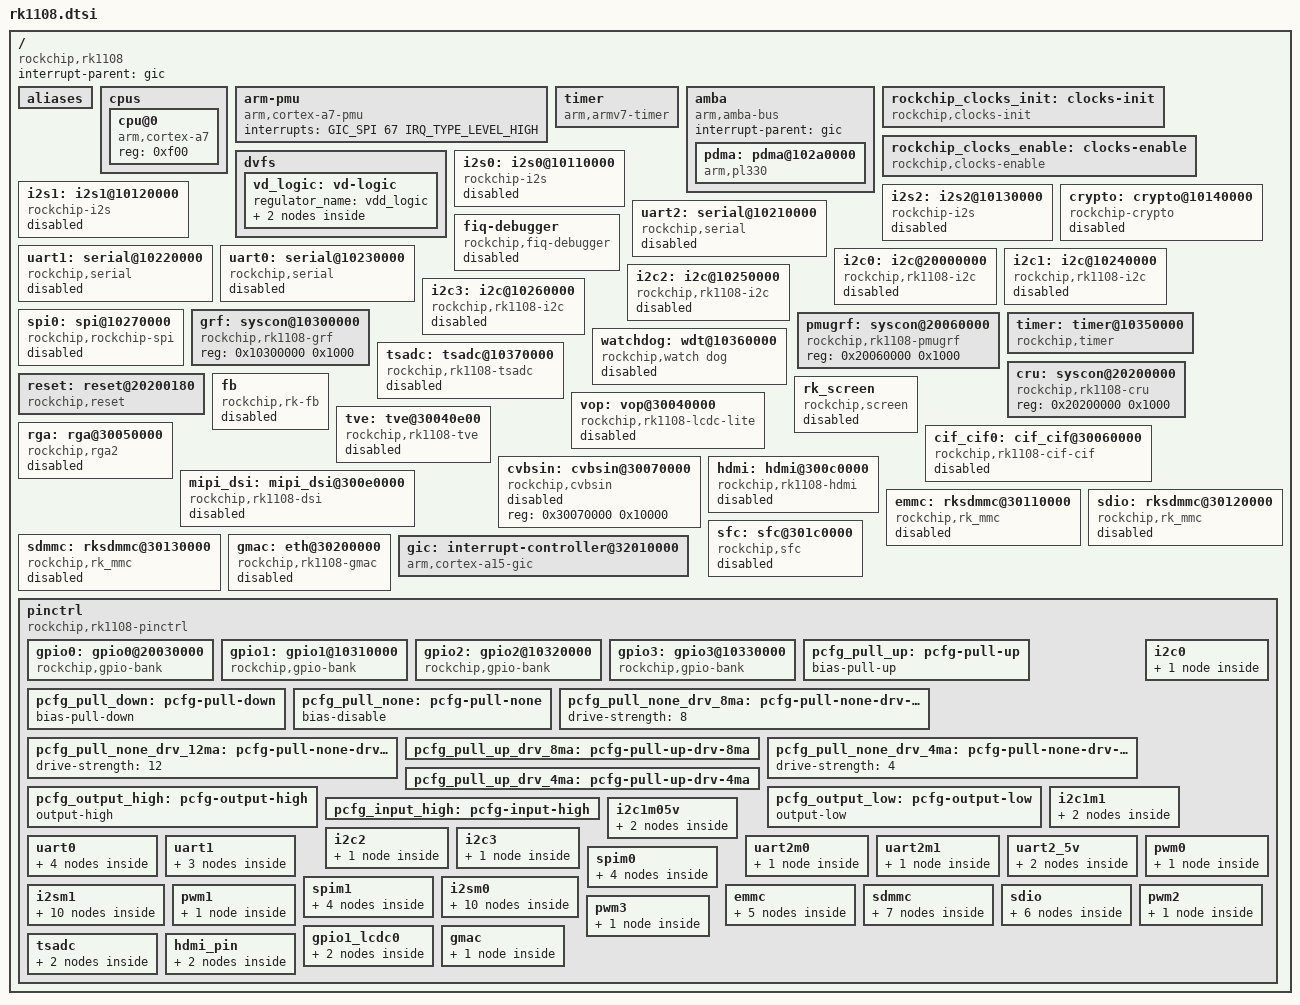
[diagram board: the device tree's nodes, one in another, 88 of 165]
/*
 * Copyright (c) 2016 Fuzhou Rockchip Electronics Co., Ltd
 *
 * This file is dual-licensed: you can use it either under the terms
 * of the GPL or the X11 license, at your option. Note that this dual
 * licensing only applies to this file, and not this project as a
 * whole.
 *
 *  a) This library is free software; you can redistribute it and/or
 *     modify it under the terms of the GNU General Public License as
 *     published by the Free Software Foundation; either version 2 of the
 *     License, or (at your option) any later version.
 *
 *     This library is distributed in the hope that it will be useful,
 *     but WITHOUT ANY WARRANTY; without even the implied warranty of
 *     MERCHANTABILITY or FITNESS FOR A PARTICULAR PURPOSE.  See the
 *     GNU General Public License for more details.
 *
 * Or, alternatively,
 *
 *  b) Permission is hereby granted, free of charge, to any person
 *     obtaining a copy of this software and associated documentation
 *     files (the "Software"), to deal in the Software without
 *     restriction, including without limitation the rights to use,
 *     copy, modify, merge, publish, distribute, sublicense, and/or
 *     sell copies of the Software, and to permit persons to whom the
 *     Software is furnished to do so, subject to the following
 *     conditions:
 *
 *     The above copyright notice and this permission notice shall be
 *     included in all copies or substantial portions of the Software.
 *
 *     THE SOFTWARE IS PROVIDED "AS IS", WITHOUT WARRANTY OF ANY KIND,
 *     EXPRESS OR IMPLIED, INCLUDING BUT NOT LIMITED TO THE WARRANTIES
 *     OF MERCHANTABILITY, FITNESS FOR A PARTICULAR PURPOSE AND
 *     NONINFRINGEMENT. IN NO EVENT SHALL THE AUTHORS OR COPYRIGHT
 *     HOLDERS BE LIABLE FOR ANY CLAIM, DAMAGES OR OTHER LIABILITY,
 *     WHETHER IN AN ACTION OF CONTRACT, TORT OR OTHERWISE, ARISING
 *     FROM, OUT OF OR IN CONNECTION WITH THE SOFTWARE OR THE USE OR
 *     OTHER DEALINGS IN THE SOFTWARE.
 */

#include <dt-bindings/pinctrl/rockchip.h>
#include <dt-bindings/gpio/gpio.h>
#include <dt-bindings/clock/rk_system_status.h>
#include <dt-bindings/interrupt-controller/arm-gic.h>
#include <dt-bindings/rkmipi/mipi_dsi.h>
#include "rk1108-clocks.dtsi"
#include "skeleton.dtsi"
#include <dt-bindings/rkfb/rk_fb.h>

/ {
	compatible = "rockchip,rk1108";
	interrupt-parent = <&gic>;

	aliases {
		i2c0 = &i2c0;
		i2c1 = &i2c1;
		i2c2 = &i2c2;
		i2c3 = &i2c3;
		serial0 = &uart0;
		serial1 = &uart1;
		serial2 = &uart2;
		spi0 = &spi0;
	};

	cpus {
		#address-cells = <1>;
		#size-cells = <0>;

		cpu@0 {
			device_type = "cpu";
			compatible = "arm,cortex-a7";
			reg = <0xf00>;
		};
	};

	arm-pmu {
		compatible = "arm,cortex-a7-pmu";
		interrupts = <GIC_SPI 67 IRQ_TYPE_LEVEL_HIGH>;
	};

	timer {
		compatible = "arm,armv7-timer";
		interrupts = <GIC_PPI 13
			      (GIC_CPU_MASK_SIMPLE(4) | IRQ_TYPE_LEVEL_HIGH)>,
			     <GIC_PPI 14
			      (GIC_CPU_MASK_SIMPLE(4) | IRQ_TYPE_LEVEL_HIGH)>;
		clock-frequency = <24000000>;
	};

	amba {
		#address-cells = <1>;
		#size-cells = <1>;
		compatible = "arm,amba-bus";
		interrupt-parent = <&gic>;
		ranges;

		pdma: pdma@102a0000 {
			compatible = "arm,pl330", "arm,primecell";
			reg = <0x102a0000 0x4000>;
			clocks = <&clk_gates12 2>;
			clock-names = "apb_pclk";
			interrupts = <GIC_SPI 0 IRQ_TYPE_LEVEL_HIGH>;
			#dma-cells = <1>;
		};
	};

	rockchip_clocks_init: clocks-init{
		compatible = "rockchip,clocks-init";
		rockchip,clocks-init-parent =
			<&aclk_bus_pre &clk_gpll>, <&aclk_peri &clk_gpll>;
		rockchip,clocks-init-rate =
			<&clk_gpll 1248000000>, <&clk_core 816000000>,
			<&clk_dsp 416000000>, <&aclk_bus_pre 156000000>,
			<&hclk_bus_pre 156000000>, <&pclk_bus_pre 78000000>,
			<&aclk_peri 156000000>, <&hclk_peri 156000000>,
			<&pclk_peri 78000000>, <&aclk_vio0_pre 312000000>,
			<&aclk_vio1_pre 312000000>, <&hclk_vio_pre 156000000>,
			<&pclk_vio_pre 156000000>, <&aclk_rkvdec_pre 312000000>,
			<&aclk_vpu_pre 312000000>, <&clk_hevc_cabac 312000000>,
			<&clk_hevc_core 312000000>, <&aclk_rkvenc_pre 312000000>,
			<&clk_venc_core 312000000>;
	};

	rockchip_clocks_enable: clocks-enable {
		compatible = "rockchip,clocks-enable";
		clocks =
			/* PLL */
			<&clk_apll>,
			<&clk_dpll>,
			<&clk_gpll>,

			/* PD_CORE */
			<&clk_core>,
			<&pclk_dbg>,
			<&aclk_core>,
			<&clk_gates11 0>, /* aclk_core_niu */
			<&clk_gates11 1>, /* pclk_core_niu */
			<&clk_gates10 9>, /* clk_ddrphy4x */

			/* PD_BUS */
			<&clk_gates12 1>, /* clk_intmem0 */
			<&clk_gates12 2>, /* aclk_dmac_bus */
			<&clk_gates12 3>, /* hclk_rom */
			<&clk_gates12 4>, /* pclk_ddr_upctl */
			<&clk_gates12 5>, /* clk_ddr_upctl */
			<&clk_gates12 6>, /* pclk_ddrmon */
			<&clk_gates12 12>, /* pclk_efuse0 */
			<&clk_gates12 13>, /* pclk_efuse1 */
			<&clk_gates14 0>, /* pclk_grf */
			<&clk_gates14 1>, /* aclk_niu */
			<&clk_gates14 2>, /* pclk_mschniu */
			<&clk_gates14 3>, /* pclk_top_niu */
			<&clk_gates14 4>, /* pclk_ddrphy */
			<&clk_gates14 5>, /* pclk_cru */
			<&clk_gates14 14>, /* pclk_usbgrf */

			/* PD_PERI */
			<&clk_gates15 11>, /* aclk_peri_niu */
			<&clk_gates15 12>, /* hclk_peri_niu */
			<&clk_gates15 13>, /* pclk_peri_niu */

			/* PD_PMU */
			<&clk_gates10 0>, /* pclk_pmu */
			<&clk_gates10 1>, /* pclk_intmem1 */
			<&clk_gates10 3>, /* pclk_pmugrf */
			<&clk_gates10 4>, /* pclk_pmu_niu */

			/* PD_DSP */
			<&clk_gates11 8>, /* aclk_dsp_edp_perf */
			<&clk_gates16 4>, /* pclk_dsp_iop_niu */
			<&clk_gates16 5>, /* aclk_dsp_epp_niu */
			<&clk_gates16 6>, /* aclk_dsp_edp_niu */
			<&clk_gates16 7>, /* pclk_dsp_dbg_niu */
			<&clk_gates16 8>, /* pclk_dsp_cfg_niu */
			<&clk_gates16 9>, /* pclk_ceva_pfm_mon */
			<&clk_gates16 14>, /* aclk_dsp_edap_niu */
			<&clk_gates16 15>, /* aclk_dsp_epp_perf */

			/* PD_VIDEO */
			<&clk_gates19 4>, /* aclk_rkvdec_niu */
			<&clk_gates19 5>, /* hclk_rkvdec_niu */
			<&clk_gates19 6>, /* aclk_vpu_niu */
			<&clk_gates19 10>, /* hclk_rkvenc_niu */
			<&clk_gates19 11>, /* aclk_rkvenc_niu */

			<&clk_gates1 9>, /* clk_timer0 */
			<&clk_gates1 10>, /* clk_timer1 */

			<&clk_gates0 3>; /* clk_jtag */
	};

	dvfs {
		vd_logic: vd-logic {
			regulator_name = "vdd_logic";
			pd_core {
				clk_core_dvfs_table: clk_core {
					operating-points = <
						/* KHz    uV */
						312000 1000000
						504000 1000000
						816000 1000000
						>;
					status = "disabled";
				};
			};
		};
	};

	i2s0: i2s0@10110000 {
		compatible = "rockchip-i2s";
		reg = <0x10110000 0x1000>;
		i2s-id = <0>;
		clocks = <&clk_i2s0>, <&i2s0_clkout>, <&clk_gates12 7>;
		clock-names = "i2s_clk", "i2s_mclk", "i2s_hclk";
		interrupts = <GIC_SPI 23 IRQ_TYPE_LEVEL_HIGH>;
		dmas = <&pdma 11>, <&pdma 12>;
		#dma-cells = <2>;
		dma-names = "tx", "rx";
		status = "disabled";
	};

	i2s1: i2s1@10120000 {
		compatible = "rockchip-i2s";
		reg = <0x10120000 0x1000>;
		i2s-id = <1>;
		clocks = <&clk_i2s1>, <&clk_gates12 8>;
		clock-names = "i2s_clk", "i2s_hclk";
		interrupts = <GIC_SPI 24 IRQ_TYPE_LEVEL_HIGH>;
		dmas = <&pdma 0>, <&pdma 1>;
		#dma-cells = <2>;
		dma-names = "tx", "rx";
		status = "disabled";
	};

	i2s2: i2s2@10130000 {
		compatible = "rockchip-i2s";
		reg = <0x10130000 0x1000>;
		i2s-id = <2>;
		clocks = <&clk_i2s2>, <&clk_gates12 9>;
		clock-names = "i2s_clk", "i2s_hclk";
		interrupts = <GIC_SPI 25 IRQ_TYPE_LEVEL_HIGH>;
		dmas = <&pdma 15>, <&pdma 16>;
		#dma-cells = <2>;
		dma-names = "tx", "rx";
		status = "disabled";
	};

	crypto: crypto@10140000 {
		compatible = "rockchip-crypto";
		reg = <0x10140000 0x10000>;
		interrupts = <GIC_SPI 26 IRQ_TYPE_LEVEL_HIGH>;
		interrupt-names = "irq_crypto";
		clocks = <&clk_crypto>, <&clk_gates12 11>, <&clk_gates12 10>;
		clock-names = "clk_crypto", "hclk_crypto", "aclk_crypto";
		status = "disabled";
	};

	uart2: serial@10210000 {
		compatible = "rockchip,serial";
		reg = <0x10210000 0x100>;
		interrupts = <GIC_SPI 46 IRQ_TYPE_LEVEL_HIGH>;
		clock-frequency = <24000000>;
		clocks = <&clk_uart2>, <&clk_gates13 12>;
		clock-names = "sclk_uart", "pclk_uart";
		reg-shift = <2>;
		reg-io-width = <4>;
		dmas = <&pdma 6>, <&pdma 7>;
		#dma-cells = <2>;
		pinctrl-names = "default";
		pinctrl-0 = <&uart2m1_xfer>;
		status = "disabled";
	};

	uart1: serial@10220000 {
		compatible = "rockchip,serial";
		reg = <0x10220000 0x100>;
		interrupts = <GIC_SPI 45 IRQ_TYPE_LEVEL_HIGH>;
		clock-frequency = <24000000>;
		clocks = <&clk_uart1>, <&clk_gates13 11>;
		clock-names = "sclk_uart", "pclk_uart";
		reg-shift = <2>;
		reg-io-width = <4>;
		dmas = <&pdma 4>, <&pdma 5>;
		#dma-cells = <2>;
		pinctrl-names = "default";
		pinctrl-0 = <&uart1_xfer &uart1_cts &uart1_rts>;
		status = "disabled";
	};

	uart0: serial@10230000 {
		compatible = "rockchip,serial";
		reg = <0x10230000 0x100>;
		interrupts = <GIC_SPI 44 IRQ_TYPE_LEVEL_HIGH>;
		clock-frequency = <24000000>;
		clocks = <&clk_uart0>, <&clk_gates13 10>;
		clock-names = "sclk_uart", "pclk_uart";
		reg-shift = <2>;
		reg-io-width = <4>;
		dmas = <&pdma 2>, <&pdma 3>;
		#dma-cells = <2>;
		pinctrl-names = "default";
		pinctrl-0 = <&uart0_xfer &uart0_cts &uart0_rts>;
		status = "disabled";
	};

	fiq-debugger {
		compatible = "rockchip,fiq-debugger";
		rockchip,serial-id = <0>;
		rockchip,signal-irq = <159>;
		rockchip,wake-irq = <0>;
		rockchip,irq-mode-enable = <0>;  /* If enable uart uses irq instead of fiq */
		rockchip,baudrate = <1500000>;  /* Only 115200 and 1500000 */
		pinctrl-names = "default";
		pinctrl-0 = <&uart0_xfer>;
		status = "disabled";
	};

	i2c0: i2c@20000000 {
		compatible = "rockchip,rk1108-i2c";
		reg = <0x20000000 0x1000>;
		interrupts = <GIC_SPI 30 IRQ_TYPE_LEVEL_HIGH>;
		#address-cells = <1>;
		#size-cells = <0>;
		clocks = <&clk_i2c0>, <&clk_gates10 5>;
		clock-names = "i2c", "pclk";
		pinctrl-names = "default";
		pinctrl-0 = <&i2c0_xfer>;
		status = "disabled";
	};

	i2c1: i2c@10240000 {
		compatible = "rockchip,rk1108-i2c";
		reg = <0x10240000 0x1000>;
		interrupts = <GIC_SPI 31 IRQ_TYPE_LEVEL_HIGH>;
		#address-cells = <1>;
		#size-cells = <0>;
		clocks = <&clk_i2c1>, <&clk_gates13 0>;
		clock-names = "i2c", "pclk";
		pinctrl-names = "default";
		pinctrl-0 = <&i2c1m1_xfer>;
		status = "disabled";
	};

	i2c2: i2c@10250000 {
		compatible = "rockchip,rk1108-i2c";
		reg = <0x10250000 0x1000>;
		interrupts = <GIC_SPI 32 IRQ_TYPE_LEVEL_HIGH>;
		#address-cells = <1>;
		#size-cells = <0>;
		clocks = <&clk_i2c2>, <&clk_gates13 1>;
		clock-names = "i2c", "pclk";
		pinctrl-names = "default";
		pinctrl-0 = <&i2c2_xfer>;
		status = "disabled";
	};

	i2c3: i2c@10260000 {
		compatible = "rockchip,rk1108-i2c";
		reg = <0x10260000 0x1000>;
		interrupts = <GIC_SPI 33 IRQ_TYPE_LEVEL_HIGH>;
		#address-cells = <1>;
		#size-cells = <0>;
		clocks = <&clk_i2c3>, <&clk_gates13 2>;
		clock-names = "i2c", "pclk";
		pinctrl-names = "default";
		pinctrl-0 = <&i2c3_xfer>;
		status = "disabled";
	};

	spi0: spi@10270000 {
		compatible = "rockchip,rockchip-spi";
		reg = <0x10270000 0x1000>;
		interrupts = <GIC_SPI 37 IRQ_TYPE_LEVEL_HIGH>;
		#address-cells = <1>;
		#size-cells = <0>;
		rockchip,spi-src-clk = <0>;
		num-cs = <2>;
		clocks =<&clk_spi>, <&clk_gates13 5>;
		clock-names = "spi", "pclk_spi0";
		status = "disabled";
	};

	grf: syscon@10300000 {
		compatible = "rockchip,rk1108-grf", "rockchip,grf", "syscon";
		reg = <0x10300000 0x1000>;
	};

	pmugrf: syscon@20060000 {
		compatible = "rockchip,rk1108-pmugrf", "rockchip,pmugrf", "syscon";
		reg = <0x20060000 0x1000>;
	};

	timer: timer@10350000 {
		compatible = "rockchip,timer";
		reg = <0x10350000 0x20>;
		interrupts = <GIC_SPI 35 IRQ_TYPE_LEVEL_HIGH>;
		rockchip,broadcast = <1>;
	};

	watchdog: wdt@10360000 {
		compatible = "rockchip,watch dog";
		reg = <0x10360000 0x100>;
		clocks = <&clk_gates13 3>;
		clock-names = "pclk_wdt";
		interrupts = <GIC_SPI 34 IRQ_TYPE_LEVEL_HIGH>;
		rockchip,irq = <1>;
		rockchip,timeout = <60>;
		rockchip,atboot = <1>;
		rockchip,debug = <0>;
		status = "disabled";
	};

	tsadc: tsadc@10370000 {
		compatible = "rockchip,rk1108-tsadc";
		reg = <0x10370000 0x100>;
		interrupts = <GIC_SPI 47 IRQ_TYPE_LEVEL_HIGH>;
		clock-frequency = <750000>;
		clocks = <&clk_tsadc>, <&clk_gates13 13>;
		clock-names = "tsadc", "pclk_tsadc";
		pinctrl-names = "default";
		pinctrl-0 = <&tsadc_gpio>;
		tsadc-ht-temp = <120>;
		tsadc-ht-reset-cru = <1>;
		tsadc-ht-pull-gpio = <0>;
		status = "disabled";
	};

	cru: syscon@20200000 {
		compatible = "rockchip,rk1108-cru", "rockchip,cru", "syscon";
		reg = <0x20200000 0x1000>;
	};

	reset: reset@20200180{
		compatible = "rockchip,reset";
		reg = <0x20200180 0x30>;
		rockchip,reset-flag = <ROCKCHIP_RESET_HIWORD_MASK>;
		#reset-cells = <1>;
	};

	fb: fb {
		status = "disabled";
		compatible = "rockchip,rk-fb";
		rockchip,disp-mode = <NO_DUAL>;
		rockchip,uboot-logo-on = <0>;
	};

	rk_screen: rk_screen {
		status = "disabled";
		compatible = "rockchip,screen";
	};

	vop: vop@30040000 {
		status = "disabled";
		compatible = "rockchip,rk1108-lcdc-lite";
		rockchip,prop = <PRMRY>;
		rockchip,pwr18 = <0>;
		rockchip,iommu-enabled = <0>;
		reg = <0x30040000 0xe00>;
		interrupts = <GIC_SPI 28 IRQ_TYPE_LEVEL_HIGH>;
		clocks = <&clk_gates18 0>, <&dclk_lcdc>, <&clk_gates18 1>;
		clock-names = "aclk_lcdc", "dclk_lcdc", "hclk_lcdc";
		pinctrl-names = "default", "gpio";
		pinctrl-0 = <&lcdc_data>;
		pinctrl-1 = <&lcdc_gpio>;
	};

	tve: tve@30040e00 {
		compatible = "rockchip,rk1108-tve";
		reg = <0x30040e00 0x100>,
		      <0x20250000 0x10000>;
		clocks = <&clk_gates14 9>;
		clock-names = "pclk_vdac";
		saturation = <0x00305b46>;
		brightcontrast = <0x00009900>;
		adjtiming = <0xd6c00880>;
		lumafilter0 = <0x02ff0001>;
		lumafilter1 = <0xf40200fe>;
		lumafilter2 = <0xf332d910>;
		daclevel = <0x15>;
		status = "disabled";
	};

	rga: rga@30050000 {
		compatible = "rockchip,rga2";
		reg = <0x30050000 0x1000>;
		interrupts = <GIC_SPI 29 IRQ_TYPE_LEVEL_HIGH>;
		clocks = <&clk_gates18 4>, <&clk_gates18 5>, <&clk_rga>;
		clock-names = "aclk_rga", "hclk_rga", "clk_rga";
		status = "disabled";
	};

	cif_cif0: cif_cif@30060000 {
		compatible = "rockchip,rk1108-cif-cif";
		rockchip,grf = <&grf>;
		cif-id = <0>;
		reg = <0x30060000 0x10000>;
		clocks = <&vip0_clk>, <&pclkin_cvbs2cif>, <&clk_gates18 6>, <&clk_gates18 7>, <&clk_gates7 9>;
		clock-names = "cif_clk", "cif_clk_parent", "aclk_cif", "hclk_cif", "pclkin_cif";
		resets = <&reset RK1108_RST_VIP0_A>, <&reset RK1108_RST_VIP0_H>, <&reset RK1108_RST_VIP0_P>;
		reset-names = "cif_arst", "cif_hrst", "cif_prst";
		interrupts = <GIC_SPI 54 IRQ_TYPE_LEVEL_HIGH>;
		interrupt-names = "irq";
		status = "disabled";
	};

	cvbsin: cvbsin@30070000 {
		compatible = "rockchip,cvbsin";
		reg = <0x30070000 0x10000>;
		device_type = "v4l2-pltfrm-subdev";
		status = "disabled";
	};

	mipi_dsi: mipi_dsi@300e0000 {
		compatible = "rockchip,rk1108-dsi";
		rockchip,prop = <0>;
		reg = <0x300e0000 0x10000>, <0x20228000 0x8000>;
		reg-names = "mipi_dsi_host", "mipi_dsi_phy";
		interrupts = <GIC_SPI 55 IRQ_TYPE_LEVEL_HIGH>;
		clocks = <&clk_gates9 10>, <&clk_gates14 11>, <&clk_gates18 8>;
		clock-names = "clk_mipi_24m", "pclk_mipi_dsi", "pclk_mipi_dsi_host";
		status = "disabled";
	};

	hdmi: hdmi@300c0000 {
		compatible = "rockchip,rk1108-hdmi";
		reg = <0x300c0000 0x20000>,
		      <0x20220000 0x10000>;
		interrupts = <GIC_SPI 21 IRQ_TYPE_LEVEL_HIGH>,
			     <GIC_SPI 22 IRQ_TYPE_LEVEL_HIGH>;
		clocks = <&clk_gates6 8>,
			 <&clk_gates18 9>,
			 <&clk_gates14 8>,
			 <&clk_hdmi_cec>;
		clock-names = "hdcp_clk_hdmi",
			      "pclk_hdmi",
			      "pclk_hdmi_phy",
			      "cec_clk_hdmi";
		pinctrl-names = "default", "gpio";
		pinctrl-0 = <&hdmi_cec &i2c1m05v_xfer &hdmi_hpd>;
		pinctrl-1 = <&i2c1m05v_gpio>;
		resets = <&reset RK1108_RST_HDMI_P>;
		reset-names = "hdmi";
		rockchip,grf = <&grf>;
		rockchip,hdmi_audio_source = <0>;
		rockchip,hdcp_enable = <0>;
		rockchip,cec_enable = <0>;
		status = "disabled";
	};

	emmc: rksdmmc@30110000 {
		compatible = "rockchip,rk_mmc", "rockchip,rk1108-sdmmc";
		reg = <0x30110000 0x10000>;
		interrupts = <GIC_SPI 13 IRQ_TYPE_LEVEL_HIGH>;
		#address-cells = <1>;
		#size-cells = <0>;
		clocks = <&clk_emmc>, <&clk_gates15 2>;
		clock-names = "clk_mmc", "hclk_mmc";
		num-slots = <1>;
		fifo-depth = <0x100>;
		bus-width = <8>;
		tune_regsbase = <0x1ec>;
		resets = <&reset RK1108_RST_EMMC_H>;
		reset-names = "mmc_ahb_reset";
		status = "disabled";
	};

	sdio: rksdmmc@30120000 {
		compatible = "rockchip,rk_mmc", "rockchip,rk1108-sdmmc";
		reg = <0x30120000 0x10000>;
		interrupts = <GIC_SPI 12 IRQ_TYPE_LEVEL_HIGH>;
		#address-cells = <1>;
		#size-cells = <0>;
		pinctrl-names = "default", "idle";
		pinctrl-0 = <&sdio_cmd &sdio_clk &sdio_bus4>;
		pinctrl-1 = <&sdio_gpio>;
		clocks = <&clk_sdio>, <&clk_gates15 1>;
		clock-names = "clk_mmc", "hclk_mmc";
		num-slots = <1>;
		fifo-depth = <0x100>;
		bus-width = <4>;
		tune_regsbase = <0x1e4>;
		resets = <&reset RK1108_RST_SDIO_H>;
		reset-names = "mmc_ahb_reset";
		status = "disabled";
	};

	sdmmc: rksdmmc@30130000 {
		compatible = "rockchip,rk_mmc", "rockchip,rk1108-sdmmc";
		reg = <0x30130000 0x10000>;
		interrupts = <GIC_SPI 11 IRQ_TYPE_LEVEL_HIGH>;
		#address-cells = <1>;
		#size-cells = <0>;
		pinctrl-names = "default", "idle";
		pinctrl-0 = <&sdmmc_clk &sdmmc_cmd &sdmmc_dectn &sdmmc_bus4 &sdmmc_pwren>;
		pinctrl-1 = <&sdmmc_gpio>;
		cd-gpios = <&gpio0 GPIO_A1 GPIO_ACTIVE_HIGH>; /* CD GPIO */
		clocks = <&clk_sdmmc>, <&clk_gates15 0>;
		clock-names = "clk_mmc", "hclk_mmc";
		num-slots = <1>;
		fifo-depth = <0x100>;
		bus-width = <4>;
		resets = <&reset RK1108_RST_SDMMC_H>;
		reset-names = "mmc_ahb_reset";
		status = "disabled";
	};

	sfc: sfc@301c0000 {
		compatible = "rockchip,sfc";
		reg = <0x301c0000 0x200>;
		interrupts = <GIC_SPI 56 IRQ_TYPE_LEVEL_HIGH>;
		clocks = <&clk_sfc>, <&clk_gates15 10>;
		clock-names = "clk_sfc", "hclk_sfc";
		status = "disabled";
	};

	gmac: eth@30200000 {
		compatible = "rockchip,rk1108-gmac";
		reg = <0x30200000 0x10000>;
		rockchip,grf = <&grf>;
		interrupts = <GIC_SPI 21 IRQ_TYPE_LEVEL_HIGH>;
		interrupt-names = "macirq";
		clocks = <&clk_mac>, <&clk_gates4 8>,
			 <&clk_gates4 8>, <&clk_gates4 6>,
			 <&clk_gates4 7>, <&clk_gates15 4>,
			 <&clk_gates15 5>;
		clock-names = "clk_mac", "mac_clk_rx",
			      "mac_clk_tx", "clk_mac_ref",
			      "clk_mac_refout", "aclk_mac",
			      "pclk_mac";
		phy-mode = "rmii";
		pinctrl-names = "default";
		pinctrl-0 = <&rmii_pins>;
		status = "disabled";
	};

	gic: interrupt-controller@32010000 {
		compatible = "arm,cortex-a15-gic";
		interrupt-controller;
		#interrupt-cells = <3>;
		#address-cells = <0>;
		reg = <0x32011000 0x1000>,
		      <0x32012000 0x1000>;
	};

	pinctrl: pinctrl {
		compatible = "rockchip,rk1108-pinctrl";
		rockchip,grf = <&grf>;
		rockchip,pmugrf = <&pmugrf>;
		#address-cells = <1>;
		#size-cells = <1>;
		ranges;

		gpio0: gpio0@20030000 {
			compatible = "rockchip,gpio-bank";
			reg = <0x20030000 0x100>;
			interrupts = <GIC_SPI 40 IRQ_TYPE_LEVEL_HIGH>;
			clocks = <&clk_gates10 2>;

			gpio-controller;
			#gpio-cells = <2>;

			interrupt-controller;
			#interrupt-cells = <2>;
		};

		gpio1: gpio1@10310000 {
			compatible = "rockchip,gpio-bank";
			reg = <0x10310000 0x100>;
			interrupts = <GIC_SPI 41 IRQ_TYPE_LEVEL_HIGH>;
			clocks = <&clk_gates13 7>;

			gpio-controller;
			#gpio-cells = <2>;

			interrupt-controller;
			#interrupt-cells = <2>;
		};

		gpio2: gpio2@10320000 {
			compatible = "rockchip,gpio-bank";
			reg = <0x10320000 0x100>;
			interrupts = <GIC_SPI 42 IRQ_TYPE_LEVEL_HIGH>;
			clocks = <&clk_gates13 8>;

			gpio-controller;
			#gpio-cells = <2>;

			interrupt-controller;
			#interrupt-cells = <2>;
		};

		gpio3: gpio3@10330000 {
			compatible = "rockchip,gpio-bank";
			reg = <0x10330000 0x100>;
			interrupts = <GIC_SPI 43 IRQ_TYPE_LEVEL_HIGH>;
			clocks = <&clk_gates13 9>;

			gpio-controller;
			#gpio-cells = <2>;

			interrupt-controller;
			#interrupt-cells = <2>;
		};

		pcfg_pull_up: pcfg-pull-up {
			bias-pull-up;
		};

		pcfg_pull_down: pcfg-pull-down {
			bias-pull-down;
		};

		pcfg_pull_none: pcfg-pull-none {
			bias-disable;
		};

		pcfg_pull_none_drv_8ma: pcfg-pull-none-drv-8ma {
			drive-strength = <8>;
		};

		pcfg_pull_none_drv_12ma: pcfg-pull-none-drv-12ma {
			drive-strength = <12>;
		};

		pcfg_pull_up_drv_8ma: pcfg-pull-up-drv-8ma {
			bias-pull-up;
			drive-strength = <8>;
		};

		pcfg_pull_none_drv_4ma: pcfg-pull-none-drv-4ma {
			drive-strength = <4>;
		};

		pcfg_pull_up_drv_4ma: pcfg-pull-up-drv-4ma {
			bias-pull-up;
			drive-strength = <4>;
		};

		pcfg_output_high: pcfg-output-high {
			output-high;
		};

		pcfg_output_low: pcfg-output-low {
			output-low;
		};

		pcfg_input_high: pcfg-input-high {
			bias-pull-up;
			input-enable;
		};

		i2c0 {
			i2c0_xfer: i2c0-xfer {
				rockchip,pins = <0 GPIO_B1 RK_FUNC_1 &pcfg_pull_none>,
						<0 GPIO_B2 RK_FUNC_1 &pcfg_pull_none>;
			};
		};

		i2c1m1 {
			i2c1m1_xfer: i2c1m1-xfer {
				rockchip,pins = <0 GPIO_C2 RK_FUNC_2 &pcfg_pull_none>,
						<0 GPIO_C6 RK_FUNC_3 &pcfg_pull_none>;
			};

			i2c1m1_gpio: i2c1m1-gpio {
				rockchip,pins = <0 GPIO_C2 RK_FUNC_GPIO &pcfg_pull_none>,
						<0 GPIO_C6 RK_FUNC_GPIO &pcfg_pull_none>;
			};
		};

		i2c1m05v {
			i2c1m05v_xfer: i2c1m05v-xfer {
				rockchip,pins = <1 GPIO_D5 RK_FUNC_2 &pcfg_pull_none>,
						<1 GPIO_D4 RK_FUNC_2 &pcfg_pull_none>;
			};

			i2c1m05v_gpio: i2c1m05v-gpio {
				rockchip,pins = <1 GPIO_D5 RK_FUNC_GPIO &pcfg_pull_none>,
						<1 GPIO_D4 RK_FUNC_GPIO &pcfg_pull_none>;
			};
		};

		i2c2 {
			i2c2_xfer: i2c2-xfer {
				rockchip,pins = <0 GPIO_B6 RK_FUNC_1 &pcfg_pull_none>,
						<0 GPIO_C4 RK_FUNC_2 &pcfg_pull_none>;
			};
		};

		i2c3 {
			i2c3_xfer: i2c3-xfer {
				rockchip,pins = <2 GPIO_D3 RK_FUNC_1 &pcfg_pull_none>,
						<2 GPIO_D4 RK_FUNC_1 &pcfg_pull_none>;
			};
		};

		uart0 {
			uart0_xfer: uart0-xfer {
				rockchip,pins = <3 GPIO_A6 RK_FUNC_1 &pcfg_pull_up>,
						<3 GPIO_A5 RK_FUNC_1 &pcfg_pull_none>;
			};

			uart0_cts: uart0-cts {
				rockchip,pins = <3 GPIO_A4 RK_FUNC_1 &pcfg_pull_none>;
			};

			uart0_rts: uart0-rts {
				rockchip,pins = <3 GPIO_A3 RK_FUNC_1 &pcfg_pull_none>;
			};

			uart0_rts_gpio: uart0-rts-gpio {
				rockchip,pins = <3 GPIO_A3 RK_FUNC_GPIO &pcfg_pull_none>;
			};
		};

		uart1 {
			uart1_xfer: uart1-xfer {
				rockchip,pins = <1 GPIO_D3 RK_FUNC_1 &pcfg_pull_up>,
						<1 GPIO_D2 RK_FUNC_1 &pcfg_pull_none>;
			};

			uart1_cts: uart1-cts {
				rockchip,pins = <1 GPIO_D0 RK_FUNC_1 &pcfg_pull_none>;
			};

			uart1_rts: uart1-rts {
				rockchip,pins = <1 GPIO_D1 RK_FUNC_1 &pcfg_pull_none>;
			};
		};

		uart2m0 {
			uart2m0_xfer: uart2m0-xfer {
				rockchip,pins = <2 GPIO_D2 RK_FUNC_1 &pcfg_pull_up>,
						<2 GPIO_D1 RK_FUNC_1 &pcfg_pull_none>;
			};
		};

		uart2m1 {
			uart2m1_xfer: uart2m1-xfer {
				rockchip,pins = <3 GPIO_C3 RK_FUNC_2 &pcfg_pull_up>,
						<3 GPIO_C2 RK_FUNC_2 &pcfg_pull_none>;
			};
		};

		uart2_5v {
			uart2_5v_cts: uart2_5v-cts {
				rockchip,pins = <1 GPIO_D4 RK_FUNC_1 &pcfg_pull_none>;
			};

			uart2_5v_rts: uart2_5v-rts {
				rockchip,pins = <1 GPIO_D5 RK_FUNC_1 &pcfg_pull_none>;
			};
		};

		spim0 {
			spim0_clk: spim0-clk {
				rockchip,pins = <1 GPIO_D0 RK_FUNC_2 &pcfg_pull_up>;
			};
			spim0_cs0: spim0-cs0 {
				rockchip,pins = <1 GPIO_D1 RK_FUNC_2 &pcfg_pull_up>;
			};
			spim0_tx: spim0-tx {
				rockchip,pins = <1 GPIO_D3 RK_FUNC_2 &pcfg_pull_up>;
			};
			spim0_rx: spim0-rx {
				rockchip,pins = <1 GPIO_D2 RK_FUNC_2 &pcfg_pull_up>;
			};
		};

		spim1 {
			spim1_clk: spim1-clk {
				rockchip,pins = <0 GPIO_A3 RK_FUNC_1 &pcfg_pull_up>;
			};
			spim1_cs0: spim1-cs0 {
				rockchip,pins = <0 GPIO_A4 RK_FUNC_1 &pcfg_pull_up>;
			};
			spim1_rx: spim1-rx {
				rockchip,pins = <0 GPIO_B0 RK_FUNC_1 &pcfg_pull_up>;
			};
			spim1_tx: spim1-tx {
				rockchip,pins = <0 GPIO_A7 RK_FUNC_1 &pcfg_pull_up>;
			};
		};

		i2sm0 {
			i2sm0_mclk: i2sm0-mclk {
				rockchip,pins = <1 GPIO_B4 RK_FUNC_2 &pcfg_pull_none>;
			};

			i2sm0_sclk:i2sm0-sclk {
				rockchip,pins = <1 GPIO_B3 RK_FUNC_2 &pcfg_pull_none>;
			};

			i2sm0_lrckrx:i2sm0-lrckrx {
				rockchip,pins = <1 GPIO_C0 RK_FUNC_2 &pcfg_pull_none>;
			};

			i2sm0_lrcktx:i2sm0-lrcktx {
				rockchip,pins = <1 GPIO_B6 RK_FUNC_2 &pcfg_pull_none>;
			};

			i2sm0_sdi:i2sm0-sdi {
				rockchip,pins = <1 GPIO_C1 RK_FUNC_2 &pcfg_pull_none>;
			};

			i2sm0_sdo0:i2sm0-sdo0 {
				rockchip,pins = <1 GPIO_B2 RK_FUNC_2 &pcfg_pull_none>;
			};

			i2sm0_sdo1:i2sm0-sdo1 {
				rockchip,pins = <1 GPIO_B5 RK_FUNC_2 &pcfg_pull_none>;
			};

			i2sm0_sdo2:i2sm0-sdo2 {
				rockchip,pins = <1 GPIO_B7 RK_FUNC_2 &pcfg_pull_none>;
			};

			i2sm0_sdo3:i2sm0-sdo3 {
				rockchip,pins = <1 GPIO_C2 RK_FUNC_2 &pcfg_pull_none>;
			};

			i2sm0_gpio: i2sm0-gpio {
				rockchip,pins = <1 GPIO_B4 RK_FUNC_GPIO &pcfg_pull_none>,
						<1 GPIO_B3 RK_FUNC_GPIO &pcfg_pull_none>,
						<1 GPIO_C0 RK_FUNC_GPIO &pcfg_pull_none>,
						<1 GPIO_B6 RK_FUNC_GPIO &pcfg_pull_none>,
						<1 GPIO_C1 RK_FUNC_GPIO &pcfg_pull_none>,
						<1 GPIO_B2 RK_FUNC_GPIO &pcfg_pull_none>,
						<1 GPIO_B5 RK_FUNC_GPIO &pcfg_pull_none>,
						<1 GPIO_B7 RK_FUNC_GPIO &pcfg_pull_none>,
						<1 GPIO_C2 RK_FUNC_GPIO &pcfg_pull_none>;
			};
		};

		i2sm1 {
			i2sm1_mclk: i2sm1-mclk {
				rockchip,pins = <2 GPIO_C5 RK_FUNC_2 &pcfg_pull_none>;
			};

			i2sm1_sclk:i2sm1-sclk {
				rockchip,pins = <2 GPIO_C4 RK_FUNC_2 &pcfg_pull_none>;
			};

			i2sm1_lrckrx:i2sm1-lrckrx {
				rockchip,pins = <2 GPIO_C0 RK_FUNC_2 &pcfg_pull_none>;
			};

			i2sm1_lrcktx:i2sm1-lrcktx {
				rockchip,pins = <1 GPIO_C6 RK_FUNC_2 &pcfg_pull_none>;
			};

			i2sm1_sdi:i2sm1-sdi {
				rockchip,pins = <2 GPIO_C1 RK_FUNC_2 &pcfg_pull_none>;
			};

			i2sm1_sdo0:i2sm1-sdo0 {
				rockchip,pins = <2 GPIO_C3 RK_FUNC_2 &pcfg_pull_none>;
			};

			i2sm1_sdo1:i2sm1-sdo1 {
				rockchip,pins = <2 GPIO_C6 RK_FUNC_2 &pcfg_pull_none>;
			};

			i2sm1_sdo2:i2sm1-sdo2 {
				rockchip,pins = <1 GPIO_C7 RK_FUNC_2 &pcfg_pull_none>;
			};

			i2sm1_sdo3:i2sm1-sdo3 {
				rockchip,pins = <3 GPIO_D3 RK_FUNC_2 &pcfg_pull_none>;
			};

			i2sm1_gpio: i2sm1-gpio {
				rockchip,pins = <2 GPIO_C5 RK_FUNC_GPIO &pcfg_pull_none>,
						<2 GPIO_C4 RK_FUNC_GPIO &pcfg_pull_none>,
						<2 GPIO_C0 RK_FUNC_GPIO &pcfg_pull_none>,
						<1 GPIO_C6 RK_FUNC_GPIO &pcfg_pull_none>,
						<2 GPIO_C1 RK_FUNC_GPIO &pcfg_pull_none>,
						<2 GPIO_C3 RK_FUNC_GPIO &pcfg_pull_none>,
						<2 GPIO_C6 RK_FUNC_GPIO &pcfg_pull_none>,
						<1 GPIO_C7 RK_FUNC_GPIO &pcfg_pull_none>,
						<3 GPIO_D3 RK_FUNC_GPIO &pcfg_pull_none>;
			};
		};

		emmc {
			emmc_clk: emmc-clk {
				rockchip,pins = <2 GPIO_B6 RK_FUNC_1 &pcfg_pull_none_drv_8ma>;
			};

			emmc_cmd: emmc-cmd {
				rockchip,pins = <2 GPIO_B4 RK_FUNC_2 &pcfg_pull_up_drv_8ma>;
			};

			emmc_pwren: emmc-pwren {
				rockchip,pins = <2 GPIO_C2 RK_FUNC_2 &pcfg_pull_none>;
			};

			emmc_bus1: emmc-bus1 {
				rockchip,pins = <2 GPIO_A0 RK_FUNC_2 &pcfg_pull_up_drv_8ma>;
			};

			emmc_bus8: emmc-bus8 {
				rockchip,pins = <2 GPIO_A0 RK_FUNC_2 &pcfg_pull_up_drv_8ma>,
						<2 GPIO_A1 RK_FUNC_2 &pcfg_pull_up_drv_8ma>,
						<2 GPIO_A2 RK_FUNC_2 &pcfg_pull_up_drv_8ma>,
						<2 GPIO_A3 RK_FUNC_2 &pcfg_pull_up_drv_8ma>,
						<2 GPIO_A4 RK_FUNC_2 &pcfg_pull_up_drv_8ma>,
						<2 GPIO_A5 RK_FUNC_2 &pcfg_pull_up_drv_8ma>,
						<2 GPIO_A6 RK_FUNC_2 &pcfg_pull_up_drv_8ma>,
						<2 GPIO_A7 RK_FUNC_2 &pcfg_pull_up_drv_8ma>;
			};
		};

		sdmmc {
			sdmmc_clk: sdmmc-clk {
				rockchip,pins = <3 GPIO_C4 RK_FUNC_1 &pcfg_pull_none_drv_4ma>;
			};

			sdmmc_cmd: sdmmc-cmd {
				rockchip,pins = <3 GPIO_C5 RK_FUNC_1 &pcfg_pull_up_drv_4ma>;
			};

			sdmmc_dectn: sdmmc-dectn {
				rockchip,pins = <0 GPIO_A1 RK_FUNC_1 &pcfg_pull_up_drv_4ma>;
			};

			sdmmc_pwren: sdmmc-pwren {
				rockchip,pins = <3 GPIO_B7 RK_FUNC_1 &pcfg_pull_up_drv_4ma>;
			};

			sdmmc_bus1: sdmmc-bus1 {
				rockchip,pins = <3 GPIO_C3 RK_FUNC_1 &pcfg_pull_up_drv_4ma>;
			};

			sdmmc_bus4: sdmmc-bus4 {
				rockchip,pins = <3 GPIO_C3 RK_FUNC_1 &pcfg_pull_up_drv_4ma>,
						<3 GPIO_C2 RK_FUNC_1 &pcfg_pull_up_drv_4ma>,
						<3 GPIO_C1 RK_FUNC_1 &pcfg_pull_up_drv_4ma>,
						<3 GPIO_C0 RK_FUNC_1 &pcfg_pull_up_drv_4ma>;
			};

			sdmmc_gpio: sdmmc-gpio {
				rockchip,pins = <3 GPIO_C4 RK_FUNC_GPIO &pcfg_pull_up_drv_4ma>,
						<3 GPIO_C5 RK_FUNC_GPIO &pcfg_pull_up_drv_4ma>,
						<0 GPIO_A1 RK_FUNC_GPIO &pcfg_pull_up_drv_4ma>,
						<3 GPIO_B7 RK_FUNC_GPIO &pcfg_pull_up_drv_4ma>,
						<3 GPIO_C3 RK_FUNC_GPIO &pcfg_pull_up_drv_4ma>,
						<3 GPIO_C2 RK_FUNC_GPIO &pcfg_pull_up_drv_4ma>,
						<3 GPIO_C1 RK_FUNC_GPIO &pcfg_pull_up_drv_4ma>,
						<3 GPIO_C0 RK_FUNC_GPIO &pcfg_pull_up_drv_4ma>;
			};
		};

		sdio {
			sdio_bus1: sdio-bus1 {
				rockchip,pins = <2 GPIO_D7 RK_FUNC_1 &pcfg_pull_up_drv_4ma>;
			};

			sdio_bus4: sdio-bus4 {
				rockchip,pins = <2 GPIO_D7 RK_FUNC_1 &pcfg_pull_up_drv_4ma>,
						<3 GPIO_A0 RK_FUNC_1 &pcfg_pull_up_drv_4ma>,
						<3 GPIO_A1 RK_FUNC_1 &pcfg_pull_up_drv_4ma>,
						<3 GPIO_A2 RK_FUNC_1 &pcfg_pull_up_drv_4ma>;
			};

			sdio_cmd: sdio-cmd {
				rockchip,pins = <2 GPIO_D6 RK_FUNC_2 &pcfg_pull_up_drv_4ma>;
			};

			sdio_clk: sdio-clk {
				rockchip,pins = <2 GPIO_D5 RK_FUNC_1 &pcfg_pull_none_drv_4ma>;
			};

			sdio_pwren: sdio-pwren {
				rockchip,pins = <0 GPIO_A2 RK_FUNC_1 &pcfg_pull_up>;
			};

			sdio_gpio: sdio-gpio {
				rockchip,pins = <2 GPIO_D7 RK_FUNC_GPIO &pcfg_pull_up_drv_4ma>,
						<3 GPIO_A0 RK_FUNC_GPIO &pcfg_pull_up_drv_4ma>,
						<3 GPIO_A1 RK_FUNC_GPIO &pcfg_pull_up_drv_4ma>,
						<3 GPIO_A2 RK_FUNC_GPIO &pcfg_pull_up_drv_4ma>,
						<2 GPIO_D6 RK_FUNC_GPIO &pcfg_pull_up_drv_4ma>,
						<2 GPIO_D5 RK_FUNC_GPIO &pcfg_pull_up_drv_4ma>,
						<0 GPIO_A2 RK_FUNC_GPIO &pcfg_pull_up_drv_4ma>;
			};
		};

		pwm0 {
			pwm0_pin: pwm0-pin {
				rockchip,pins = <0 GPIO_C5 RK_FUNC_1 &pcfg_pull_none>;
			};
		};

		pwm1 {
			pwm1_pin: pwm1-pin {
				rockchip,pins = <0 GPIO_C4 RK_FUNC_1 &pcfg_pull_none>;
			};
		};

		pwm2 {
			pwm2_pin: pwm2-pin {
				rockchip,pins = <0 GPIO_C6 RK_FUNC_1 &pcfg_pull_none>;
			};
		};

		pwm3 {
			pwm3_pin: pwm3-pin {
				rockchip,pins = <0 GPIO_C0 RK_FUNC_1 &pcfg_pull_none>;
			};
		};

		gpio1_lcdc0 {
			lcdc_data: lcdc-data {
				rockchip,pins = <1 GPIO_C5 RK_FUNC_1 &pcfg_pull_none>,//DCLK
						<1 GPIO_A0 RK_FUNC_1 &pcfg_pull_none>,//D0
						<1 GPIO_A1 RK_FUNC_1 &pcfg_pull_none>,//D1
						<1 GPIO_A2 RK_FUNC_1 &pcfg_pull_none>,//D2
						<1 GPIO_A3 RK_FUNC_1 &pcfg_pull_none>,//D3
						<1 GPIO_A4 RK_FUNC_1 &pcfg_pull_none>,//D4
						<1 GPIO_A5 RK_FUNC_1 &pcfg_pull_none>,//D5
						<1 GPIO_A6 RK_FUNC_1 &pcfg_pull_none>,//D6
						<1 GPIO_A7 RK_FUNC_1 &pcfg_pull_none>,//D7
						<1 GPIO_B0 RK_FUNC_1 &pcfg_pull_none>,//D8
						<1 GPIO_B1 RK_FUNC_1 &pcfg_pull_none>,//D9
						<1 GPIO_C4 RK_FUNC_1 &pcfg_pull_none>,//HSYNC
						<1 GPIO_C3 RK_FUNC_1 &pcfg_pull_none>,//VSYNC
						<1 GPIO_C2 RK_FUNC_1 &pcfg_pull_none>,//DEN
						<1 GPIO_C1 RK_FUNC_1 &pcfg_pull_none>,//D10
						<1 GPIO_C0 RK_FUNC_1 &pcfg_pull_none>,//D11
						<1 GPIO_B7 RK_FUNC_1 &pcfg_pull_none>,//D12
						<1 GPIO_B6 RK_FUNC_1 &pcfg_pull_none>,//D13
						<1 GPIO_B5 RK_FUNC_1 &pcfg_pull_none>,//D14
						<1 GPIO_B4 RK_FUNC_1 &pcfg_pull_none>,//D15
						<1 GPIO_B3 RK_FUNC_1 &pcfg_pull_none>,//D16
						<1 GPIO_B2 RK_FUNC_1 &pcfg_pull_none>;//D17
			};

			lcdc_gpio: lcdc-gpio {
				rockchip,pins = <1 GPIO_C5 RK_FUNC_GPIO &pcfg_pull_none>,//DCLK
						<1 GPIO_A0 RK_FUNC_GPIO &pcfg_pull_none>,//D0
						<1 GPIO_A1 RK_FUNC_GPIO &pcfg_pull_none>,//D1
						<1 GPIO_A2 RK_FUNC_GPIO &pcfg_pull_none>,//D2
						<1 GPIO_A3 RK_FUNC_GPIO &pcfg_pull_none>,//D3
						<1 GPIO_A4 RK_FUNC_GPIO &pcfg_pull_none>,//D4
						<1 GPIO_A5 RK_FUNC_GPIO &pcfg_pull_none>,//D5
						<1 GPIO_A6 RK_FUNC_GPIO &pcfg_pull_none>,//D6
						<1 GPIO_A7 RK_FUNC_GPIO &pcfg_pull_none>,//D7
						<1 GPIO_B0 RK_FUNC_GPIO &pcfg_pull_none>,//D8
						<1 GPIO_B1 RK_FUNC_GPIO &pcfg_pull_none>,//D9
						<1 GPIO_C4 RK_FUNC_GPIO &pcfg_pull_none>,//HSYNC
						<1 GPIO_C3 RK_FUNC_GPIO &pcfg_pull_none>,//VSYNC
						<1 GPIO_C2 RK_FUNC_GPIO &pcfg_pull_none>,//DEN
						<1 GPIO_C1 RK_FUNC_GPIO &pcfg_pull_none>,//D10
						<1 GPIO_C0 RK_FUNC_GPIO &pcfg_pull_none>,//D11
						<1 GPIO_B7 RK_FUNC_GPIO &pcfg_pull_none>,//D12
						<1 GPIO_B6 RK_FUNC_GPIO &pcfg_pull_none>,//D13
						<1 GPIO_B5 RK_FUNC_GPIO &pcfg_pull_none>,//D14
						<1 GPIO_B4 RK_FUNC_GPIO &pcfg_pull_none>,//D15
						<1 GPIO_B3 RK_FUNC_GPIO &pcfg_pull_none>,//D16
						<1 GPIO_B2 RK_FUNC_GPIO &pcfg_pull_none>;//D17
			};
		};

		gmac {
			rmii_pins: rmii-pins {
				rockchip,pins =	<1 GPIO_C5 RK_FUNC_2 &pcfg_pull_none>,
						<1 GPIO_C3 RK_FUNC_2 &pcfg_pull_none>,
						<1 GPIO_C4 RK_FUNC_2 &pcfg_pull_none>,
						<1 GPIO_B2 RK_FUNC_3 &pcfg_pull_none_drv_12ma>,
						<1 GPIO_B3 RK_FUNC_3 &pcfg_pull_none_drv_12ma>,
						<1 GPIO_B4 RK_FUNC_3 &pcfg_pull_none_drv_12ma>,
						<1 GPIO_B5 RK_FUNC_3 &pcfg_pull_none>,
						<1 GPIO_B6 RK_FUNC_3 &pcfg_pull_none>,
						<1 GPIO_B7 RK_FUNC_3 &pcfg_pull_none>,
						<1 GPIO_C2 RK_FUNC_3 &pcfg_pull_none>;
			};
		};

		tsadc {
			tsadc_int: tsadc-int {
				rockchip,pins =	<0 GPIO_B7 RK_FUNC_1 &pcfg_pull_none>;
			};
			tsadc_gpio: tsadc-gpio {
				rockchip,pins =	<0 GPIO_B7 RK_FUNC_GPIO &pcfg_pull_none>;
			};
		};

		hdmi_pin {
			hdmi_cec: hdmi-cec {
				rockchip,pins = <1 GPIO_D7 RK_FUNC_1 &pcfg_pull_none>;
			};

			hdmi_hpd: hdmi-hpd {
				rockchip,pins = <1 GPIO_D6 RK_FUNC_1 &pcfg_pull_down>;
			};
		};
	};
};
